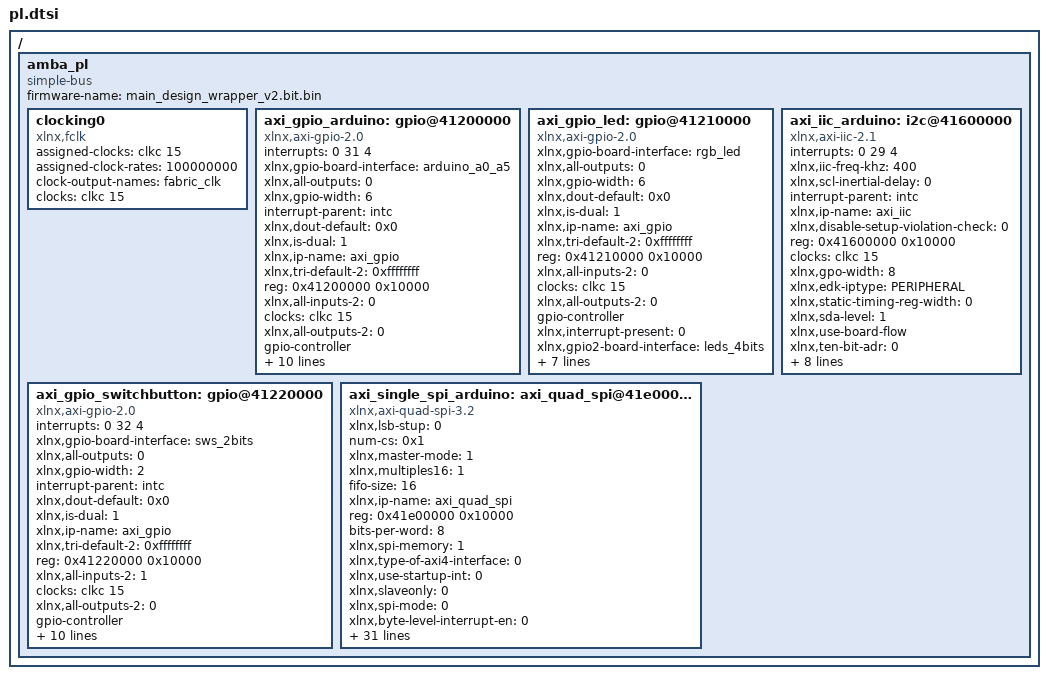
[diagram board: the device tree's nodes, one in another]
/ {
	amba_pl: amba_pl {
		ranges;
		compatible = "simple-bus";
		#address-cells = <1>;
		#size-cells = <1>;
		firmware-name = "main_design_wrapper_v2.bit.bin";
		clocking0: clocking0 {
			compatible = "xlnx,fclk";
			assigned-clocks = <&clkc 15>;
			assigned-clock-rates = <100000000>;
			#clock-cells = <0>;
			clock-output-names = "fabric_clk";
			clocks = <&clkc 15>;
		};
		axi_gpio_arduino: gpio@41200000 {
			#interrupt-cells = <2>;
			interrupts = < 0 31 4 >;
			xlnx,gpio-board-interface = "arduino_a0_a5";
			compatible = "xlnx,axi-gpio-2.0" , "xlnx,xps-gpio-1.00.a";
			xlnx,all-outputs = <0>;
			#gpio-cells = <2>;
			xlnx,gpio-width = <6>;
			interrupt-parent = <&intc>;
			xlnx,dout-default = <0x0>;
			xlnx,is-dual = <1>;
			xlnx,ip-name = "axi_gpio";
			xlnx,tri-default-2 = <0xffffffff>;
			reg = <0x41200000 0x10000>;
			xlnx,all-inputs-2 = <0>;
			clocks = <&clkc 15>;
			xlnx,all-outputs-2 = <0>;
			gpio-controller;
			xlnx,interrupt-present = <1>;
			xlnx,gpio2-board-interface = "arduino_ar0_ar13";
			xlnx,edk-iptype = "PERIPHERAL";
			xlnx,dout-default-2 = <0x0>;
			status = "okay";
			xlnx,gpio2-width = <14>;
			clock-names = "s_axi_aclk";
			xlnx,use-board-flow;
			interrupt-controller;
			interrupt-names = "ip2intc_irpt";
			xlnx,tri-default = <0xffffffff>;
			xlnx,name = "axi_gpio_arduino";
			xlnx,all-inputs = <0>;
		};
		axi_gpio_led: gpio@41210000 {
			xlnx,gpio-board-interface = "rgb_led";
			compatible = "xlnx,axi-gpio-2.0" , "xlnx,xps-gpio-1.00.a";
			xlnx,all-outputs = <0>;
			#gpio-cells = <2>;
			xlnx,gpio-width = <6>;
			xlnx,dout-default = <0x0>;
			xlnx,is-dual = <1>;
			xlnx,ip-name = "axi_gpio";
			xlnx,tri-default-2 = <0xffffffff>;
			reg = <0x41210000 0x10000>;
			xlnx,all-inputs-2 = <0>;
			clocks = <&clkc 15>;
			xlnx,all-outputs-2 = <0>;
			gpio-controller;
			xlnx,interrupt-present = <0>;
			xlnx,gpio2-board-interface = "leds_4bits";
			xlnx,edk-iptype = "PERIPHERAL";
			xlnx,dout-default-2 = <0x0>;
			status = "okay";
			xlnx,gpio2-width = <4>;
			clock-names = "s_axi_aclk";
			xlnx,use-board-flow;
			xlnx,tri-default = <0xffffffff>;
			xlnx,name = "axi_gpio_led";
			xlnx,all-inputs = <0>;
		};
		axi_gpio_switchbutton: gpio@41220000 {
			#interrupt-cells = <2>;
			interrupts = < 0 32 4 >;
			xlnx,gpio-board-interface = "sws_2bits";
			compatible = "xlnx,axi-gpio-2.0" , "xlnx,xps-gpio-1.00.a";
			xlnx,all-outputs = <0>;
			#gpio-cells = <2>;
			xlnx,gpio-width = <2>;
			interrupt-parent = <&intc>;
			xlnx,dout-default = <0x0>;
			xlnx,is-dual = <1>;
			xlnx,ip-name = "axi_gpio";
			xlnx,tri-default-2 = <0xffffffff>;
			reg = <0x41220000 0x10000>;
			xlnx,all-inputs-2 = <1>;
			clocks = <&clkc 15>;
			xlnx,all-outputs-2 = <0>;
			gpio-controller;
			xlnx,interrupt-present = <1>;
			xlnx,gpio2-board-interface = "btns_4bits";
			xlnx,edk-iptype = "PERIPHERAL";
			xlnx,dout-default-2 = <0x0>;
			status = "okay";
			xlnx,gpio2-width = <4>;
			clock-names = "s_axi_aclk";
			xlnx,use-board-flow;
			interrupt-controller;
			interrupt-names = "ip2intc_irpt";
			xlnx,tri-default = <0xffffffff>;
			xlnx,name = "axi_gpio_switchbutton";
			xlnx,all-inputs = <1>;
		};
		axi_iic_arduino: i2c@41600000 {
			interrupts = < 0 29 4 >;
			xlnx,iic-freq-khz = <400>;
			compatible = "xlnx,axi-iic-2.1" , "xlnx,xps-iic-2.00.a";
			xlnx,scl-inertial-delay = <0>;
			interrupt-parent = <&intc>;
			xlnx,ip-name = "axi_iic";
			xlnx,disable-setup-violation-check = <0>;
			reg = <0x41600000 0x10000>;
			clocks = <&clkc 15>;
			xlnx,gpo-width = <8>;
			xlnx,edk-iptype = "PERIPHERAL";
			xlnx,static-timing-reg-width = <0>;
			xlnx,sda-level = <1>;
			status = "okay";
			clock-names = "s_axi_aclk";
			xlnx,use-board-flow;
			xlnx,ten-bit-adr = <0>;
			xlnx,default-value = <0x0>;
			interrupt-names = "iic2intc_irpt";
			xlnx,iic-board-interface = "i2c";
			xlnx,timing-reg-width = <32>;
			xlnx,iic-freq = <400000>;
			xlnx,smbus-pmbus-host = <0>;
			xlnx,name = "axi_iic_arduino";
			xlnx,axi-aclk-freq-mhz = <100>;
			xlnx,sda-inertial-delay = <0>;
		};
		axi_single_spi_arduino: axi_quad_spi@41e00000 {
			xlnx,lsb-stup = <0>;
			num-cs = <0x1>;
			xlnx,master-mode = <1>;
			xlnx,multiples16 = <1>;
			fifo-size = <16>;
			xlnx,ip-name = "axi_quad_spi";
			reg = <0x41e00000 0x10000>;
			bits-per-word = <8>;
			xlnx,spi-memory = <1>;
			xlnx,type-of-axi4-interface = <0>;
			xlnx,use-startup-int = <0>;
			xlnx,slaveonly = <0>;
			xlnx,spi-mode = <0>;
			interrupt-names = "ip2intc_irpt";
			compatible = "xlnx,axi-quad-spi-3.2" , "xlnx,xps-spi-2.00.a";
			xlnx,byte-level-interrupt-en = <0>;
			xlnx,s-axi4-addr-width = <24>;
			xlnx,sck-ratio = <16>;
			interrupt-parent = <&intc>;
			xlnx,async-clk = <0>;
			status = "okay";
			xlnx,sck-ratio1 = <1>;
			xlnx,use-board-flow;
			xlnx,name = "axi_single_spi_arduino";
			xlnx,fifo-included = <1>;
			interrupts = < 0 30 1 >;
			xlnx,use-startup-ext = <0>;
			xlnx,hasfifos = <1>;
			xlnx,s-axi4-id-width = <4>;
			xlnx,shared-startup = <0>;
			xlnx,new-seq-en = <1>;
			xlnx,qspi-board-interface = "spi";
			clocks = <&clkc 15>, <&clkc 15>;
			xlnx,edk-iptype = "PERIPHERAL";
			xlnx,fifo-depth = <16>;
			clock-names = "ext_spi_clk" , "s_axi_aclk";
			xlnx,axi-interface = <0>;
			xlnx,num-ss-bits = <0x1>;
			xlnx,select-xpm = <0>;
			xlnx,xip-mode = <0>;
			xlnx,xip-perf-mode = <1>;
			xlnx,dual-quad-mode = <0>;
			xlnx,num-transfer-bits = <8>;
			xlnx,s-axi4-data-width = <32>;
			xlnx,use-startup = <0>;
			xlnx,spi-mem-addr-bits = <24>;
			xlnx,uc-family = <0>;
			xlnx,Axi4-address = <0>;
			xlnx,sub-family = "zynq";
		};
	};
};
